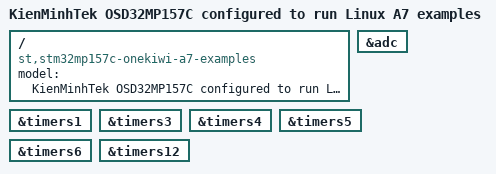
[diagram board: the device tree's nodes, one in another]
// SPDX-License-Identifier: (GPL-2.0+ OR BSD-3-Clause)
/*
 * Copyright (C) STMicroelectronics 2017 - All Rights Reserved
 * Author: Alexandre Torgue <alexandre.torgue@st.com> for STMicroelectronics.
 */

/dts-v1/;

#include "stm32mp157c-onekiwi.dts"

/ {
	model = "KienMinhTek OSD32MP157C configured to run Linux A7 examples";
	compatible = "st,stm32mp157c-onekiwi-a7-examples", "st,stm32mp157c-onekiwi", "st,stm32mp157";
};

&adc {
	status = "okay";
};

&timers1 {
	status = "okay";
};

&timers3 {
	status = "okay";
};

&timers4 {
	status = "okay";
};

&timers5 {
	status = "okay";
};

&timers6 {
	status = "okay";
};

&timers12 {
	status = "okay";
};
